# STM32H7x5_CM4 register map
File version: 1.1
CPU: CM4 r0p1, little endian, MPU, FPU, 4 interrupt priority bits
Registers are 32-bit, read-write, reset 0x0 unless marked. A register's access mark holds for its fields unless they carry their own. Offsets are from the block's base; [hi:lo] are bit positions; {n}, {i} and the like mark numbered series.

## TIM6 — Basic timers
Base 0x40001000
Same registers: TIM7 0x40001400
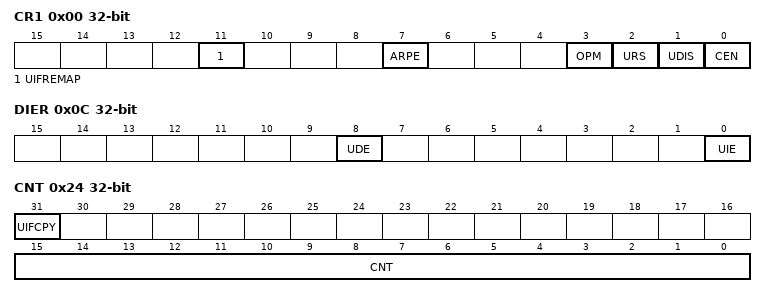
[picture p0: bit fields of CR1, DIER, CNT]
0x00 CR1 — control register 1
  [11] UIFREMAP — UIF status bit remapping
  [7] ARPE — Auto-reload preload enable
  [3] OPM — One-pulse mode
  [2] URS — Update request source
  [1] UDIS — Update disable
  [0] CEN — Counter enable
0x04 CR2 — control register 2
  [6:4] MMS — Master mode selection
0x0C DIER — DMA/Interrupt enable register
  [8] UDE — Update DMA request enable
  [0] UIE — Update interrupt enable
0x10 SR — status register
  [0] UIF — Update interrupt flag
0x14 EGR wo — event generation register
  [0] UG — Update generation
0x24 CNT — counter
  [31] UIFCPY — UIF Copy
  [15:0] CNT — Low counter value
0x28 PSC — prescaler
  [15:0] PSC — Prescaler value
0x2C ARR — auto-reload register
  [15:0] ARR — Low Auto-reload value

## NVIC — Nested Vectored Interrupt Controller
Base 0xE000E100
{0x0+4i} ISER{i} (i=0..2) — Interrupt Set-Enable Register
  [31:0] SETENA
0x0C ISER3 — Interrupt Set-Enable Register
{0x80+4i} ICER{i} (i=0..2) — Interrupt Clear-Enable Register
  [31:0] CLRENA
0x8C ICER3 — Interrupt Clear-Enable Register
{0x100+4i} ISPR{i} (i=0..2) — Interrupt Set-Pending Register
  [31:0] SETPEND
0x10C ISPR3 — Interrupt Set-Pending Register
{0x180+4i} ICPR{i} (i=0..2) — Interrupt Clear-Pending Register
  [31:0] CLRPEND
0x1C0 ICPR3 — Interrupt Clear-Pending Register
{0x200+4i} IABR{i} ro (i=0..2) — Interrupt Active Bit Register
  [31:0] ACTIVE
0x20C IABR3 — Interrupt Active Bit Register
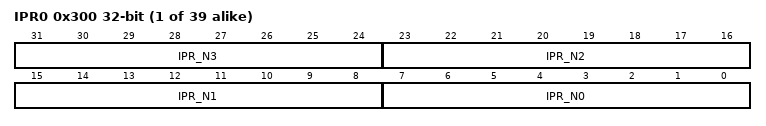
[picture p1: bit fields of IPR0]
{0x300+4i} IPR{i} (i=0..38) — Interrupt Priority Register
  [8n+7:8n] IPR_N{n} (n=0..3)

## MPU — Memory protection unit
Base 0xE000ED90
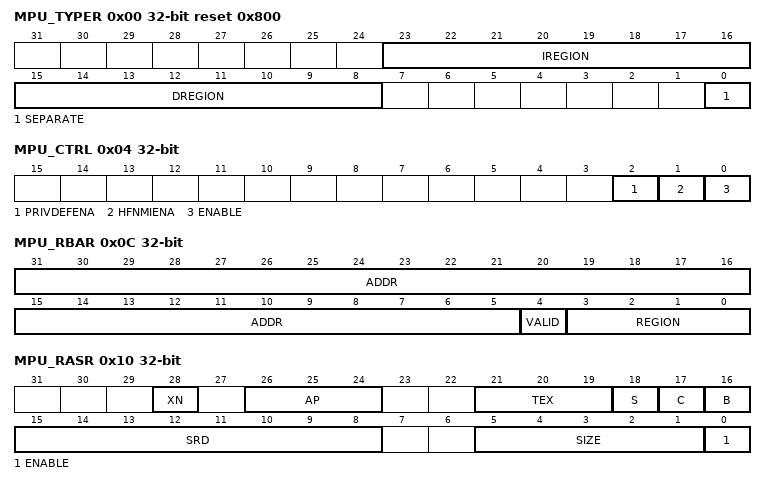
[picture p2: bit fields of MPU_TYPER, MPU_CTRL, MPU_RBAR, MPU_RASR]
0x00 MPU_TYPER ro reset 0x800 — MPU type register
  [23:16] IREGION — Number of MPU instruction regions
  [15:8] DREGION — Number of MPU data regions
  [0] SEPARATE — Separate flag
0x04 MPU_CTRL ro — MPU control register
  [2] PRIVDEFENA — Enable priviliged software access to default memory map
  [1] HFNMIENA — Enables the operation of MPU during hard fault
  [0] ENABLE — Enables the MPU
0x08 MPU_RNR — MPU region number register
  [7:0] REGION — MPU region
0x0C MPU_RBAR — MPU region base address register
  [31:5] ADDR — Region base address field
  [4] VALID — MPU region number valid
  [3:0] REGION — MPU region field
0x10 MPU_RASR — MPU region attribute and size register
  [28] XN — Instruction access disable bit
  [26:24] AP — Access permission
  [21:19] TEX — memory attribute
  [18] S — Shareable memory attribute
  [17] C — memory attribute
  [16] B — memory attribute
  [15:8] SRD — Subregion disable bits
  [5:1] SIZE — Size of the MPU protection region
  [0] ENABLE — Region enable bit.

## STK — SysTick timer
Base 0xE000E010
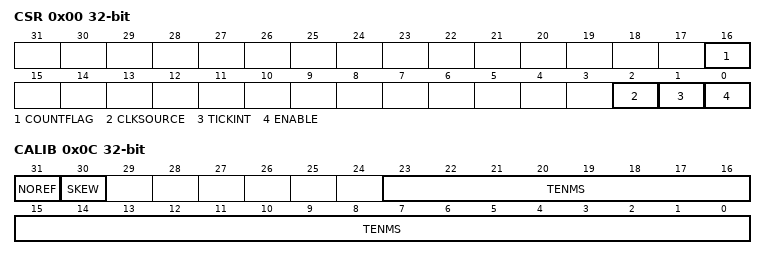
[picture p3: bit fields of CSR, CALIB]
0x00 CSR — SysTick control and status register
  [16] COUNTFLAG
  [2] CLKSOURCE — Clock source selection
  [1] TICKINT — SysTick exception request enable
  [0] ENABLE — Counter enable
0x04 RVR — SysTick reload value register
  [23:0] RELOAD — RELOAD value
0x08 CVR — SysTick current value register
  [23:0] CURRENT — Current counter value
0x0C CALIB — SysTick calibration value register
  [31] NOREF — NOREF flag. Reads as zero
  [30] SKEW — SKEW flag: Indicates whether the TENMS value is exact
  [23:0] TENMS — Calibration value

## NVIC_STIR — Nested vectored interrupt controller
Base 0xE000EF00
0x00 STIR — Software trigger interrupt register
  [8:0] INTID — Software generated interrupt ID

## FPU_CPACR — Floating point unit CPACR
Base 0xE000ED88
0x00 CPACR — Coprocessor access control register
  [23:20] CP

## SCB_ACTRL — System control block ACTLR
Base 0xE000E008
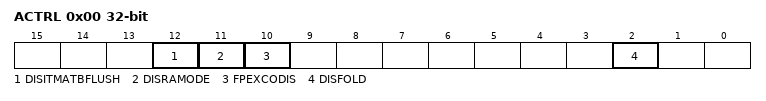
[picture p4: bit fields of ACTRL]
0x00 ACTRL — Auxiliary control register
  [12] DISITMATBFLUSH, [11] DISRAMODE, [10] FPEXCODIS, [2] DISFOLD
